# AT32F490xx_v2 register map
Vendor: Keil; Series: AT32F490; File version: 1.0
CPU: CM4 r0p1, little endian, no MPU, FPU, 4 interrupt priority bits
Registers are 32-bit, read-write, reset 0x0 unless marked. A register's access mark holds for its fields unless they carry their own. Offsets are from the block's base; [hi:lo] are bit positions.

## DVP — Digital video parallel interface
Base 0x50050000
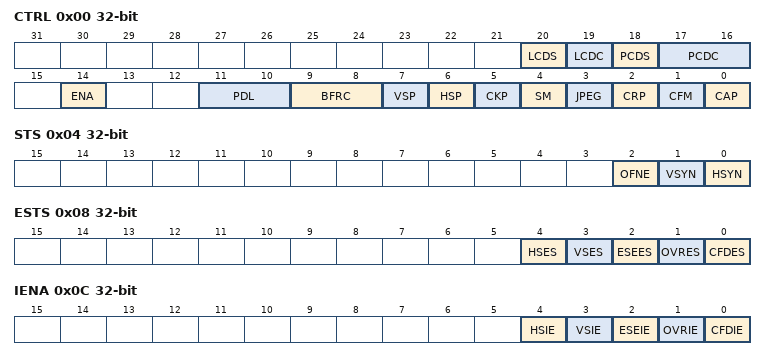
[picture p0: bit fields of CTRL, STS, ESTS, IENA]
0x00 CTRL — Control register
  [20] LCDS — Line capture/drop selection
  [19] LCDC — Line capture/drop control
  [18] PCDS — Pixel capture/drop selection
  [17:16] PCDC — Basic pixel capture/drop control
  [14] ENA — DVP enable
  [11:10] PDL — Pixel data length
  [9:8] BFRC — Basic frame rate control
  [7] VSP — Vertical synchronization polarity
  [6] HSP — Horizontal synchronization polarity
  [5] CKP — Pixel clock polarity
  [4] SM — synchronization mode
  [3] JPEG — JPEG format
  [2] CRP — Cropping function enable
  [1] CFM — Capture fire mode
  [0] CAP — Capture function enable
0x04 STS ro — status register
  [2] OFNE — Output FIFO Non-empty
  [1] VSYN — Vertical synchronization status
  [0] HSYN — Horizontal synchronization status
0x08 ESTS ro — Event status register
  [4] HSES — Horizontal synchronization event status
  [3] VSES — Vertical synchronization event status
  [2] ESEES — Embedded synchronization error event status
  [1] OVRES — Data FIFO overrun event status
  [0] CFDES — Capture frame done event status
0x0C IENA — interrupt enable register
  [4] HSIE — Horizontal synchronization interrupt enable
  [3] VSIE — Vertical synchronization interrupt enablee
  [2] ESEIE — Embedded synchronization error interrupt enable
  [1] OVRIE — Data FIFO overrun interrupt enable
  [0] CFDIE — Capture frame done interrupt enable
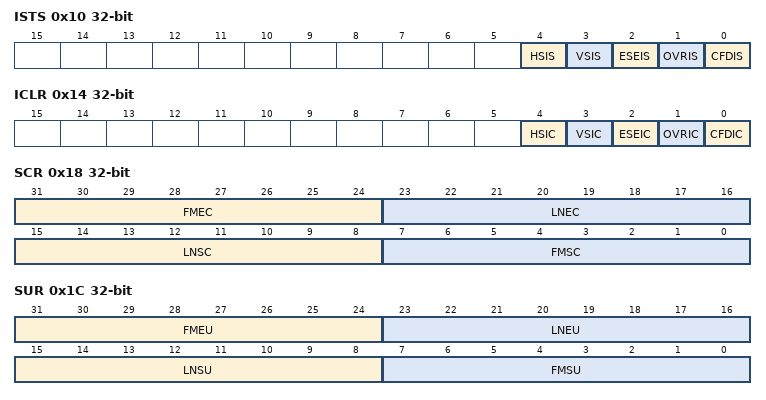
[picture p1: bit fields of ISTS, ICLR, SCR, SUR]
0x10 ISTS ro — Interrupt status register
  [4] HSIS — Horizontal synchronization interrupt status
  [3] VSIS — Vertical synchronization interrupt status
  [2] ESEIS — Embedded synchronization error interrupt status
  [1] OVRIS — Data FIFO overrun interrupt status
  [0] CFDIS — Capture frame done interrupt status
0x14 ICLR wo — Interrupt clear register
  [4] HSIC — Horizontal synchronization interrupt clear
  [3] VSIC — Vertical synchronization interrupt clear
  [2] ESEIC — Embedded synchronization error interrupt clear
  [1] OVRIC — Data FIFO overrun interrupt clear
  [0] CFDIC — Capture frame done interrupt clear
0x18 SCR — Synchronization code register
  [31:24] FMEC — Frame end code
  [23:16] LNEC — Line end code
  [15:8] LNSC — Line start code
  [7:0] FMSC — Frame start code
0x1C SUR — Synchronization unmask register
  [31:24] FMEU — Frame end unmask
  [23:16] LNEU — Line end unmask
  [15:8] LNSU — Line start unmask
  [7:0] FMSU — Frame start unmask
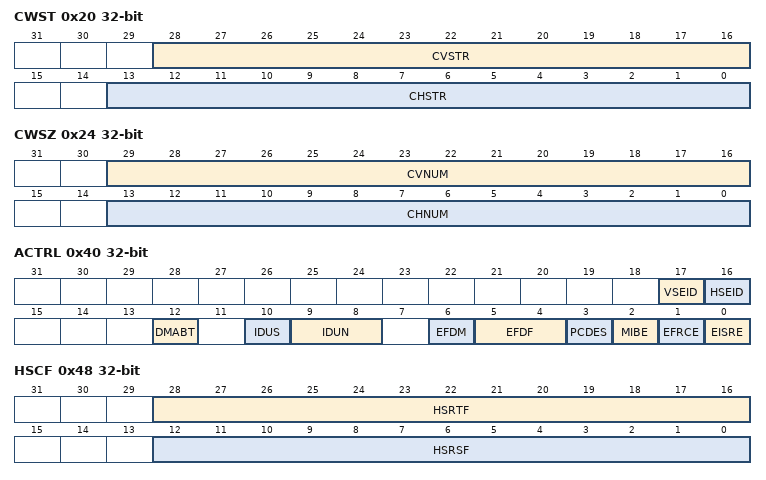
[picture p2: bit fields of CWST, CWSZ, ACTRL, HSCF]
0x20 CWST — Crop window start
  [28:16] CVSTR — Cropping window vertical start line
  [13:0] CHSTR — Cropping window horizontal start pixel
0x24 CWSZ — Crop window size
  [29:16] CVNUM — Cropping window vertical line number
  [13:0] CHNUM — Cropping window horizontal pixel number
0x28 DT ro — Data register
  [31:0] DT — Data Port
0x40 ACTRL — Advanced Control register
  [17] VSEID — Vertical synchonization event and interrupt definition
  [16] HSEID — Horizontal synchonization event and interrupt definition
  [12] DMABT — DMA burst transfer configuration
  [10] IDUS — Input data un-used setting
  [9:8] IDUN — Input data un-used number
  [6] EFDM — Enhanced function data format management
  [5:4] EFDF — Enhanced function data format
  [3] PCDES — Basic pixel capture/drop extended selection
  [2] MIBE — Monochrome image binarization enable
  [1] EFRCE — Enhanced frame rate control enable
  [0] EISRE — Enhanced image scaling resize enable
0x48 HSCF — Horizontal scaling control flow
  [28:16] HSRTF — Horizontal scaling resize target factor
  [12:0] HSRSF — Horizontal scaling resize source factor
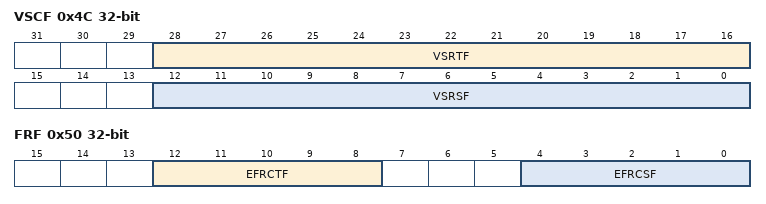
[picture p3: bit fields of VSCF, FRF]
0x4C VSCF — Vertical scaling control flow
  [28:16] VSRTF — Vertical scaling resize target factor
  [12:0] VSRSF — Vertical scaling resize source factor
0x50 FRF — Frame rate flow
  [12:8] EFRCTF — Enhanced frame rate control target factor
  [4:0] EFRCSF — Enhanced frame rate contorl source factor
0x54 BTH — Binarization threshold
  [7:0] MIBTHD — Monochrome image binarization threshold

## Notices in the file
Copyright (C) 2012-2014 ARM Limited. All rights reserved.
Purpose: System Viewer Description (SVD) Example (Schema Version 1.1)
This is a description of a none-existent and incomplete device
for demonstration purposes only.
Redistribution and use in source and binary forms, with or without
modification, are permitted provided that the following conditions are met:
- Redistributions of source code must retain the above copyright
notice, this list of conditions and the following disclaimer.
- Redistributions in binary form must reproduce the above copyright
notice, this list of conditions and the following disclaimer in the
documentation and/or other materials provided with the distribution.
- Neither the name of ARM nor the names of its contributors may be used
to endorse or promote products derived from this software without
specific prior written permission.
THIS SOFTWARE IS PROVIDED BY THE COPYRIGHT HOLDERS AND CONTRIBUTORS "AS IS"
AND ANY EXPRESS OR IMPLIED WARRANTIES, INCLUDING, BUT NOT LIMITED TO, THE
IMPLIED WARRANTIES OF MERCHANTABILITY AND FITNESS FOR A PARTICULAR PURPOSE
ARE DISCLAIMED. IN NO EVENT SHALL COPYRIGHT HOLDERS AND CONTRIBUTORS BE
LIABLE FOR ANY DIRECT, INDIRECT, INCIDENTAL, SPECIAL, EXEMPLARY, OR
CONSEQUENTIAL DAMAGES (INCLUDING, BUT NOT LIMITED TO, PROCUREMENT OF
SUBSTITUTE GOODS OR SERVICES; LOSS OF USE, DATA, OR PROFITS; OR BUSINESS
INTERRUPTION) HOWEVER CAUSED AND ON ANY THEORY OF LIABILITY, WHETHER IN
CONTRACT, STRICT LIABILITY, OR TORT (INCLUDING NEGLIGENCE OR OTHERWISE)
ARISING IN ANY WAY OUT OF THE USE OF THIS SOFTWARE, EVEN IF ADVISED OF THE
POSSIBILITY OF SUCH DAMAGE.
